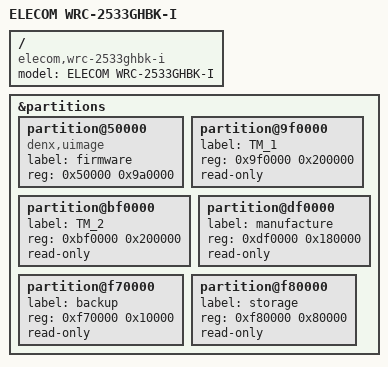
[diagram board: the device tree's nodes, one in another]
// SPDX-License-Identifier: GPL-2.0-or-later OR MIT

#include "mt7621_elecom_wrc-2533ghbk.dtsi"

/ {
	compatible = "elecom,wrc-2533ghbk-i", "mediatek,mt7621-soc";
	model = "ELECOM WRC-2533GHBK-I";
};

&partitions {
	partition@50000 {
		compatible = "denx,uimage";
		label = "firmware";
		reg = <0x50000 0x9a0000>;
	};

	partition@9f0000 {
		label = "TM_1";
		reg = <0x9f0000 0x200000>;
		read-only;
	};

	partition@bf0000 {
		label = "TM_2";
		reg = <0xbf0000 0x200000>;
		read-only;
	};

	partition@df0000 {
		label = "manufacture";
		reg = <0xdf0000 0x180000>;
		read-only;
	};

	partition@f70000 {
		label = "backup";
		reg = <0xf70000 0x10000>;
		read-only;
	};

	partition@f80000 {
		label = "storage";
		reg = <0xf80000 0x80000>;
		read-only;
	};
};
